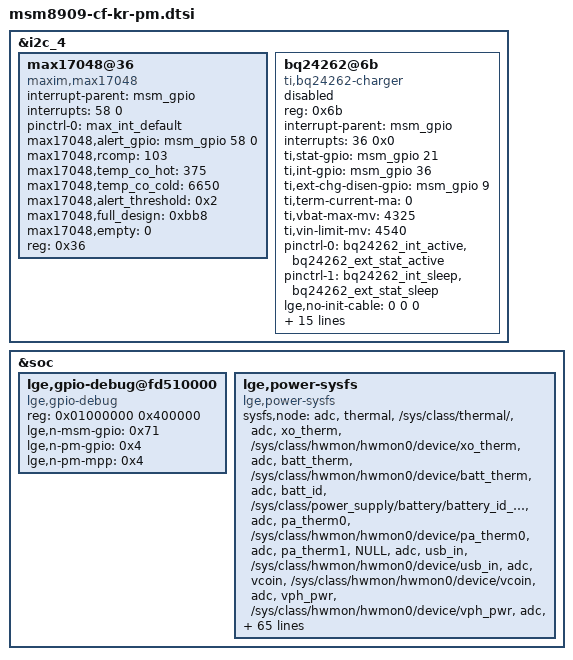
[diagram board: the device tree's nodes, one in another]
/* Copyright (c) 2014, The Linux Foundation. All rights reserved.
 *
 * This program is free software; you can redistribute it and/or modify
 * it under the terms of the GNU General Public License version 2 and
 * only version 2 as published by the Free Software Foundation.
 *
 * This program is distributed in the hope that it will be useful,
 * but WITHOUT ANY WARRANTY; without even the implied warranty of
 * MERCHANTABILITY or FITNESS FOR A PARTICULAR PURPOSE.  See the
 * GNU General Public License for more details.
 */

&i2c_4 {
	/* BLSP1 QUP4 */
	max17048@36 {
		compatible = "maxim,max17048";
		interrupt-parent = <&msm_gpio>;
		interrupts = <58 0>;
		pinctrl-names = "default";
		pinctrl-0 = <&max_int_default>;
		max17048,alert_gpio = <&msm_gpio 58 0>;
		max17048,rcomp = <103>;
		max17048,temp_co_hot = <375>;
		max17048,temp_co_cold = <6650>;
		max17048,alert_threshold = <0x2>;
		max17048,full_design = <0xbb8>;
		max17048,empty = <0>;
		reg = <0x36>;
	};

	bq24262@6b {
		status = "disabled";
		compatible = "ti,bq24262-charger";
		reg = <0x6b>;
		interrupt-parent = <&msm_gpio>;
		interrupts = <36 0x0>;
		ti,stat-gpio = <&msm_gpio 21 0>;
		ti,int-gpio = <&msm_gpio 36 0>;
		ti,ext-chg-disen-gpio = <&msm_gpio 9 0>;
		ti,term-current-ma = <0>;
		ti,vbat-max-mv = <4325>;	/* Step unit 20 mV, battery available voltage(x = 4.375) : x-0.025 ~ x ~ x+0.025 */
		ti,vin-limit-mv = <4540>;
		/* Pins config setting */
		pinctrl-names = "default", "sleep";
		pinctrl-0 = <&bq24262_int_active &bq24262_ext_stat_active>;
		pinctrl-1 = <&bq24262_int_sleep &bq24262_ext_stat_sleep>;

		/* Each model is defferently value */
		lge,no-init-cable = <0 0 0>;
		lge,cable-mhl-1k = <5000 500 500>;
		lge,cable-u-28p7k = <5500 1200 500>;
		lge,cable-28p7k = <6000 1200 500>;
		lge,cable-56k = <200000 1500 1500>;
		lge,cable-100k = <239000 1200 500>;
		lge,cable-130k = <340000 1500 1500>;
		lge,cable-180k = <400000 1200 500>;
		lge,cable-200k = <410000 1200 500>;
		lge,cable-220k = <485000 1200 500>;
		lge,cable-270k = <560000 1200 500>;
		lge,cable-330k = <735000 1200 500>;
		lge,cable-620k = <955000 1200 500>;
		lge,cable-910k = <1140000 1500 1500>;
		lge,cable-none = <1900000 1200  500>;

		qcom,bq24262-vadc = <&pm8909_vadc>;
	};
};

&soc {
	lge,gpio-debug@fd510000 {
		compatible = "lge,gpio-debug";
		reg = <0x01000000 0x400000>;
		reg-names = "tlmm-base";
		lge,n-msm-gpio = <0x71>;
		lge,n-pm-gpio = <0x4>;
		lge,n-pm-mpp = <0x4>;
	};
};

&soc {
	lge,power-sysfs {
		compatible = "lge,power-sysfs";

		sysfs,node =
			/* group , user_node,  kernel node */
			/* ADC/MPP */
			"adc", "thermal", "/sys/class/thermal/",
			"adc", "xo_therm", "/sys/class/hwmon/hwmon0/device/xo_therm",
			"adc", "batt_therm", "/sys/class/hwmon/hwmon0/device/batt_therm",
			"adc", "batt_id", "/sys/class/power_supply/battery/battery_id_checker",
			"adc", "pa_therm0", "/sys/class/hwmon/hwmon0/device/pa_therm0",
			"adc", "pa_therm1", "NULL",
			"adc", "usb_in", "/sys/class/hwmon/hwmon0/device/usb_in",
			"adc", "vcoin", "/sys/class/hwmon/hwmon0/device/vcoin",
			"adc", "vph_pwr", "/sys/class/hwmon/hwmon0/device/vph_pwr",
			"adc", "usb_id", "/sys/class/hwmon/hwmon0/device/usb_id",
			/* Battery */
			"battery", "capacity", "/sys/class/power_supply/battery/capacity",
			"battery", "health", "/sys/class/power_supply/battery/health",
			"battery", "present", "/sys/class/power_supply/battery/present",
			"battery", "pseudo_batt", "/sys/class/power_supply/battery/pseudo_batt",
			"battery", "status", "/sys/class/power_supply/battery/status",
			"battery", "temp", "/sys/class/power_supply/battery/temp",
			"battery", "valid_batt_id", "/sys/class/power_supply/battery/valid_batt_id",
			"battery", "voltage_now", "/sys/class/power_supply/battery/voltage_now",
			/* Charger */
			"charger", "ac_online", "NULL",
			"charger", "usb_online", "/sys/class/power_supply/usb/online",
			"charger", "present", "/sys/class/power_supply/usb/present",
			"charger", "wlc_online", "NULL",
			"charger", "type", "/sys/class/power_supply/usb/type",
			"charger", "time_out", "NULL",
			"charger", "charging_enabled", "/sys/class/power_supply/battery/charging_enabled",
			"charger", "ibat_current", "/sys/class/power_supply/battery/current_now",
			"charger", "ichg_current", "/sys/class/power_supply/usb/current_max",
			"charger", "iusb_control", "NULL",
			"charger", "thermal_mitigation", "/sys/module/qpnp_linear_charger/parameters/qpnp_thermal_mitigation",
			"charger", "wlc_thermal_mitigation", "NULL",
			"charger", "usb_parallel_chg_status", "NULL",
			"charger", "usb_parallel_charging_enabled", "NULL",
			/* LCD Backlight */
			"lcd", "brightness", "/sys/class/leds/lcd-backlight/brightness",
			"lcd", "max_brightness", "/sys/class/leds/lcd-backlight/max_brightness",
			/* KEY LED */
			"key_led", "red_brightness", "/sys/class/leds/R/brightness",
			"key_led", "green_brightness", "/sys/class/leds/G/brightness",
			"key_led", "blue_brightness", "/sys/class/leds/B/brightness",
			/* CPU */
			"cpu", "cpu_idle_modes", "NULL",
			/* GPU */
			"gpu", "busy", "/sys/class/kgsl/kgsl-3d0/gpubusy",
			/* PLATFORM */
			"platform", "speed_bin", "NULL",
			"platform", "pvs_bin", "NULL",
			"platform", "power_state", "/sys/power/autosleep",
			"platform", "poweron_alarm", "/sys/module/qpnp_rtc/parameters/poweron_alarm",
			"platform", "pcb_rev", "/sys/class/hwmon/hwmon0/device/pcb_rev",
			/* testmode */
			"testmode", "charge", "/sys/class/power_supply/battery/device/at_charge",
			"testmode", "chcomp", "/sys/class/power_supply/battery/device/at_chcomp",
			"testmode", "chgmodeoff", "/sys/class/power_supply/battery/charging_enabled",
			"testmode", "fuelrst", "NULL",
			"testmode", "rtc_time", "/dev/rtc0",
			"testmode", "pmrst", "NULL",
			"testmode", "battexit", "/sys/class/power_supply/battery/present"
			;
	};
};
